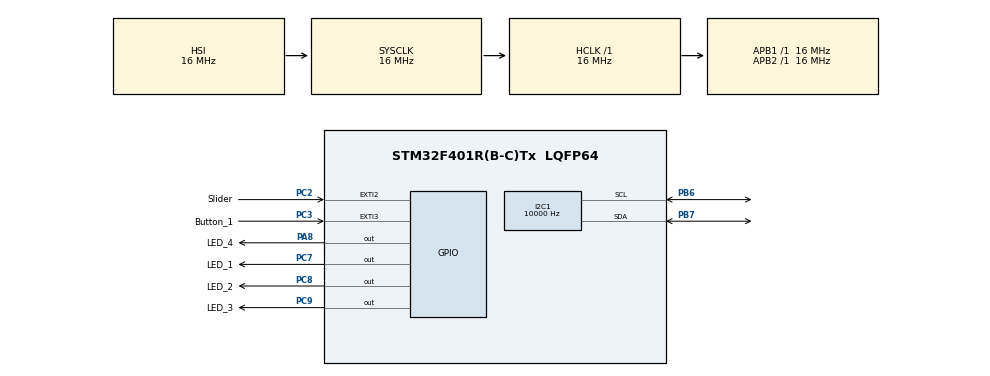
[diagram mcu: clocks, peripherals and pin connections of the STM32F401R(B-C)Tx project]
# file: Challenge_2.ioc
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I2C1.ClockSpeed=10000
Mcu.Family=STM32F4
Mcu.Name=STM32F401R(B-C)Tx
Mcu.Package=LQFP64
NVIC.EXTI2_IRQn=true\:0\:0\:false\:false\:true\:true\:true\:true
NVIC.EXTI3_IRQn=true\:0\:0\:false\:false\:true\:true\:true\:true
NVIC.PriorityGroup=NVIC_PRIORITYGROUP_4
NVIC.TIM2_IRQn=true\:0\:0\:false\:false\:true\:true\:true\:true
PA13.Mode=Serial_Wire
PA13.Signal=SYS_JTMS-SWDIO
PA14.Mode=Serial_Wire
PA14.Signal=SYS_JTCK-SWCLK
PA8.GPIO_Label=LED_4
PA8.PinState=GPIO_PIN_SET
PA8.Signal=GPIO_Output
PB6.GPIO_Pu=GPIO_PULLUP
PB6.Mode=I2C
PB6.Signal=I2C1_SCL
PB7.GPIO_Pu=GPIO_PULLUP
PB7.Mode=I2C
PB7.Signal=I2C1_SDA
PC14-OSC32_IN.Mode=LSE-External-Clock-Source
PC14-OSC32_IN.Signal=RCC_OSC32_IN
PC15-OSC32_OUT.Mode=LSE-External-Clock-Source
PC15-OSC32_OUT.Signal=RCC_OSC32_OUT
PC2.GPIO_Label=Slider
PC2.GPIO_ModeDefaultEXTI=GPIO_MODE_IT_RISING_FALLING
PC2.Signal=GPXTI2
PC3.GPIO_Label=Button_1
PC3.GPIO_ModeDefaultEXTI=GPIO_MODE_IT_RISING_FALLING
PC3.Signal=GPXTI3
PC7.GPIO_Label=LED_1
PC7.PinState=GPIO_PIN_SET
PC7.Signal=GPIO_Output
PC8.GPIO_Label=LED_2
PC8.PinState=GPIO_PIN_SET
PC8.Signal=GPIO_Output
PC9.GPIO_Label=LED_3
PC9.PinState=GPIO_PIN_SET
PC9.Signal=GPIO_Output
PH0\ -\ OSC_IN.Mode=HSE-External-Clock-Source
PH0\ -\ OSC_IN.Signal=RCC_OSC_IN
PH1\ -\ OSC_OUT.Mode=HSE-External-Clock-Source
PH1\ -\ OSC_OUT.Signal=RCC_OSC_OUT
ProjectManager.HeapSize=0x200
ProjectManager.StackSize=0x400
ProjectManager.TargetToolchain=STM32CubeIDE
RCC.AHBFreq_Value=16000000
RCC.APB1Freq_Value=16000000
RCC.APB1TimFreq_Value=16000000
RCC.APB2Freq_Value=16000000
RCC.APB2TimFreq_Value=16000000
RCC.CortexFreq_Value=16000000
RCC.HCLKFreq_Value=16000000
RCC.HSE_VALUE=25000000
RCC.HSI_VALUE=16000000
RCC.LSE_VALUE=32768
RCC.SYSCLKFreq_VALUE=16000000
RCC.VCOOutputFreq_Value=192000000
TIM2.AutoReloadPreload=TIM_AUTORELOAD_PRELOAD_ENABLE
TIM2.Period=125-1
TIM2.Prescaler=64000-1
VP_TIM2_VS_ClockSourceINT.Mode=Internal
board=custom

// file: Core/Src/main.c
/* USER CODE BEGIN Header */
/**
  ******************************************************************************
  * @file           : main.c
  * @brief          : Main program body
  ******************************************************************************
  * @attention
  *
  * Copyright (c) 2026 STMicroelectronics.
  * All rights reserved.
  *
  * This software is licensed under terms that can be found in the LICENSE file
  * in the root directory of this software component.
  * If no LICENSE file comes with this software, it is provided AS-IS.
  *
  ******************************************************************************
  */
/* USER CODE END Header */
#include "main.h"
#include "i2c.h"
#include "tim.h"
#include "gpio.h"

/* USER CODE BEGIN Includes */

#include "Manager.h"

/* USER CODE END Includes */

void SystemClock_Config(void);

int main(void)
{

  /* MCU Configuration--------------------------------------------------------*/

  /* Reset of all peripherals, Initializes the Flash interface and the Systick. */
  HAL_Init();

  /* Configure the system clock */
  SystemClock_Config();

  /* Initialize all configured peripherals */
  MX_GPIO_Init();
  MX_TIM2_Init();
  MX_I2C1_Init();
  /* USER CODE BEGIN 2 */
  Manager_Initialize();
  /* USER CODE END 2 */

  /* Infinite loop */
  /* USER CODE BEGIN WHILE */
  while (1)
  {

	  Manager_Loop();
    /* USER CODE END WHILE */

  }
}

void SystemClock_Config(void)
{
  RCC_OscInitTypeDef RCC_OscInitStruct = {0};
  RCC_ClkInitTypeDef RCC_ClkInitStruct = {0};

  /** Configure the main internal regulator output voltage
  */
  __HAL_RCC_PWR_CLK_ENABLE();
  __HAL_PWR_VOLTAGESCALING_CONFIG(PWR_REGULATOR_VOLTAGE_SCALE2);

  /** Initializes the RCC Oscillators according to the specified parameters
  * in the RCC_OscInitTypeDef structure.
  */
  RCC_OscInitStruct.OscillatorType = RCC_OSCILLATORTYPE_HSI;
  RCC_OscInitStruct.HSIState = RCC_HSI_ON;
  RCC_OscInitStruct.HSICalibrationValue = RCC_HSICALIBRATION_DEFAULT;
  RCC_OscInitStruct.PLL.PLLState = RCC_PLL_NONE;
  if (HAL_RCC_OscConfig(&RCC_OscInitStruct) != HAL_OK)
  {
    Error_Handler();
  }

  /** Initializes the CPU, AHB and APB buses clocks
  */
  RCC_ClkInitStruct.ClockType = RCC_CLOCKTYPE_HCLK|RCC_CLOCKTYPE_SYSCLK
                              |RCC_CLOCKTYPE_PCLK1|RCC_CLOCKTYPE_PCLK2;
  RCC_ClkInitStruct.SYSCLKSource = RCC_SYSCLKSOURCE_HSI;
  RCC_ClkInitStruct.AHBCLKDivider = RCC_SYSCLK_DIV1;
  RCC_ClkInitStruct.APB1CLKDivider = RCC_HCLK_DIV1;
  RCC_ClkInitStruct.APB2CLKDivider = RCC_HCLK_DIV1;

  if (HAL_RCC_ClockConfig(&RCC_ClkInitStruct, FLASH_LATENCY_0) != HAL_OK)
  {
    Error_Handler();
  }
}

void Error_Handler(void)
{
  __disable_irq();
  while (1)
  {
  }
}
